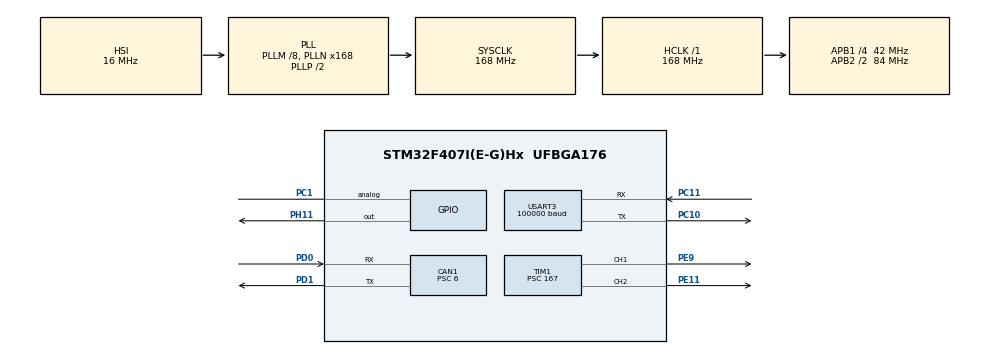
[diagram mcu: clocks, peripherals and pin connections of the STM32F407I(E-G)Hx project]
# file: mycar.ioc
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CAN1.BS1=CAN_BS1_3TQ
CAN1.BS2=CAN_BS2_3TQ
CAN1.CalculateBaudRate=1000000
CAN1.CalculateTimeBit=1000
CAN1.CalculateTimeQuantum=142.85714285714286
CAN1.Prescaler=6
Dma.Request0=USART3_RX
Dma.USART3_RX.0.Direction=DMA_PERIPH_TO_MEMORY
Dma.USART3_RX.0.FIFOMode=DMA_FIFOMODE_DISABLE
Dma.USART3_RX.0.Instance=DMA1_Stream1
Dma.USART3_RX.0.MemDataAlignment=DMA_MDATAALIGN_BYTE
Dma.USART3_RX.0.MemInc=DMA_MINC_ENABLE
Dma.USART3_RX.0.Mode=DMA_NORMAL
Dma.USART3_RX.0.PeriphDataAlignment=DMA_PDATAALIGN_BYTE
Dma.USART3_RX.0.PeriphInc=DMA_PINC_DISABLE
Dma.USART3_RX.0.Priority=DMA_PRIORITY_LOW
FREERTOS.INCLUDE_eTaskGetState=1
FREERTOS.INCLUDE_pcTaskGetTaskName=1
FREERTOS.INCLUDE_uxTaskGetStackHighWaterMark=1
FREERTOS.INCLUDE_vTaskCleanUpResources=1
FREERTOS.INCLUDE_vTaskDelayUntil=1
FREERTOS.INCLUDE_xEventGroupSetBitFromISR=1
FREERTOS.INCLUDE_xQueueGetMutexHolder=1
FREERTOS.INCLUDE_xSemaphoreGetMutexHolder=1
FREERTOS.INCLUDE_xTaskAbortDelay=1
FREERTOS.INCLUDE_xTaskGetCurrentTaskHandle=1
FREERTOS.INCLUDE_xTaskGetHandle=1
FREERTOS.INCLUDE_xTimerPendFunctionCall=1
FREERTOS.Tasks01=defaultTask,0,128,StartDefaultTask,Default,NULL,Dynamic,NULL,NULL;gimbaltask,2,256,Startgimbaltask,Default,NULL,Dynamic,NULL,NULL;chassistask,2,256,Startchassistask,Default,NULL,Dynamic,NULL,NULL;decodeTask,3,256,StartdecodeTask,Default,NULL,Dynamic,NULL,NULL;sendTask,0,128,StartsendTask,Default,NULL,Dynamic,NULL,NULL;modeTask,1,256,StartmodeTask,Default,NULL,Dynamic,NULL,NULL
FREERTOS.configUSE_TIMERS=1
Mcu.Family=STM32F4
Mcu.Name=STM32F407I(E-G)Hx
Mcu.Package=UFBGA176
NVIC.CAN1_RX0_IRQn=true\:5\:0\:false\:false\:true\:true\:true\:true\:true
NVIC.DMA1_Stream1_IRQn=true\:5\:0\:false\:false\:true\:true\:false\:true\:true
NVIC.PriorityGroup=NVIC_PRIORITYGROUP_4
NVIC.TIM2_IRQn=true\:15\:0\:false\:false\:true\:false\:false\:true\:true
NVIC.TimeBase=TIM2_IRQn
NVIC.TimeBaseIP=TIM2
NVIC.USART3_IRQn=true\:5\:0\:false\:false\:true\:true\:true\:true\:true
PA13.Mode=Serial_Wire
PA13.Signal=SYS_JTMS-SWDIO
PA14.Mode=Serial_Wire
PA14.Signal=SYS_JTCK-SWCLK
PC1.Signal=GPIO_Analog
PC10.Mode=Asynchronous
PC10.Signal=USART3_TX
PC11.Mode=Asynchronous
PC11.Signal=USART3_RX
PD0.Mode=CAN_Activate
PD0.Signal=CAN1_RX
PD1.Mode=CAN_Activate
PD1.Signal=CAN1_TX
PE11.Signal=S_TIM1_CH2
PE9.Signal=S_TIM1_CH1
PH0-OSC_IN.Mode=HSE-External-Oscillator
PH0-OSC_IN.Signal=RCC_OSC_IN
PH1-OSC_OUT.Mode=HSE-External-Oscillator
PH1-OSC_OUT.Signal=RCC_OSC_OUT
PH11.GPIO_PuPd=GPIO_PULLUP
PH11.PinState=GPIO_PIN_SET
PH11.Signal=GPIO_Output
ProjectManager.HeapSize=0x200
ProjectManager.StackSize=0x400
ProjectManager.TargetToolchain=CMake
RCC.48MHZClocksFreq_Value=84000000
RCC.AHBFreq_Value=168000000
RCC.APB1CLKDivider=RCC_HCLK_DIV4
RCC.APB1Freq_Value=42000000
RCC.APB1TimFreq_Value=84000000
RCC.APB2CLKDivider=RCC_HCLK_DIV2
RCC.APB2Freq_Value=84000000
RCC.APB2TimFreq_Value=168000000
RCC.CortexFreq_Value=168000000
RCC.HCLKFreq_Value=168000000
RCC.HSE_VALUE=12000000
RCC.HSI_VALUE=16000000
RCC.LSE_VALUE=32768
RCC.PLLM=8
RCC.PLLN=168
RCC.SYSCLKFreq_VALUE=168000000
RCC.SYSCLKSource=RCC_SYSCLKSOURCE_PLLCLK
RCC.VCOOutputFreq_Value=336000000
SH.S_TIM1_CH1.0=TIM1_CH1,PWM Generation1 CH1
SH.S_TIM1_CH2.0=TIM1_CH2,PWM Generation2 CH2
STMicroelectronics.X-CUBE-ALGOBUILD.1.5.0.LibraryCcDSPOoLibraryJjDSPOoLibrary=true
TIM1.AutoReloadPreload=TIM_AUTORELOAD_PRELOAD_ENABLE
TIM1.Channel-PWM\ Generation1\ CH1=TIM_CHANNEL_1
TIM1.Channel-PWM\ Generation2\ CH2=TIM_CHANNEL_2
TIM1.Period=19999
TIM1.Prescaler=167
TIM1.Pulse-PWM\ Generation1\ CH1=1500
TIM1.Pulse-PWM\ Generation2\ CH2=1500
USART3.BaudRate=100000
USART3.Parity=PARITY_EVEN
USART3.VirtualMode=VM_ASYNC
USART3.WordLength=WORDLENGTH_9B
VP_FREERTOS_VS_CMSIS_V1.Mode=CMSIS_V1
VP_STMicroelectronics.X-CUBE-ALGOBUILD_VS_DSPOoLibraryJjLibrary_1.5.0_1.5.0.Mode=DSPOoLibraryJjLibrary
VP_SYS_VS_tim2.Mode=TIM2
VP_TIM1_VS_ClockSourceINT.Mode=Internal
board=custom

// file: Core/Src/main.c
/* USER CODE BEGIN Header */
/**
  ******************************************************************************
  * @file           : main.c
  * @brief          : Main program body
  ******************************************************************************
  * @attention
  *
  * Copyright (c) 2026 STMicroelectronics.
  * All rights reserved.
  *
  * This software is licensed under terms that can be found in the LICENSE file
  * in the root directory of this software component.
  * If no LICENSE file comes with this software, it is provided AS-IS.
  *
  ******************************************************************************
  */
/* USER CODE END Header */
#include "main.h"
#include "cmsis_os.h"
#include "can.h"
#include "dma.h"
#include "tim.h"
#include "usart.h"
#include "gpio.h"

/* USER CODE BEGIN Includes */
#include "bsp_dwt.h"
#include "mycar.h"
/* USER CODE END Includes */

void SystemClock_Config(void);
void MX_FREERTOS_Init(void);

int main(void)
{

  /* MCU Configuration--------------------------------------------------------*/

  /* Reset of all peripherals, Initializes the Flash interface and the Systick. */
  HAL_Init();

  /* Configure the system clock */
  SystemClock_Config();

  /* Initialize all configured peripherals */
  MX_GPIO_Init();
  MX_DMA_Init();
  MX_CAN1_Init();
  MX_USART3_UART_Init();
  MX_TIM1_Init();
  /* USER CODE BEGIN 2 */

  DWT_Init(168);
  TotalCar_Init();
  /* USER CODE END 2 */

  /* Call init function for freertos objects (in cmsis_os2.c) */
  MX_FREERTOS_Init();

  /* Start scheduler */
  osKernelStart();

  /* We should never get here as control is now taken by the scheduler */

  /* Infinite loop */
  while (1)
  {

  }
}

void SystemClock_Config(void)
{
  RCC_OscInitTypeDef RCC_OscInitStruct = {0};
  RCC_ClkInitTypeDef RCC_ClkInitStruct = {0};

  /** Configure the main internal regulator output voltage
  */
  __HAL_RCC_PWR_CLK_ENABLE();
  __HAL_PWR_VOLTAGESCALING_CONFIG(PWR_REGULATOR_VOLTAGE_SCALE1);

  /** Initializes the RCC Oscillators according to the specified parameters
  * in the RCC_OscInitTypeDef structure.
  */
  RCC_OscInitStruct.OscillatorType = RCC_OSCILLATORTYPE_HSI;
  RCC_OscInitStruct.HSIState = RCC_HSI_ON;
  RCC_OscInitStruct.HSICalibrationValue = RCC_HSICALIBRATION_DEFAULT;
  RCC_OscInitStruct.PLL.PLLState = RCC_PLL_ON;
  RCC_OscInitStruct.PLL.PLLSource = RCC_PLLSOURCE_HSI;
  RCC_OscInitStruct.PLL.PLLM = 8;
  RCC_OscInitStruct.PLL.PLLN = 168;
  RCC_OscInitStruct.PLL.PLLP = RCC_PLLP_DIV2;
  RCC_OscInitStruct.PLL.PLLQ = 4;
  if (HAL_RCC_OscConfig(&RCC_OscInitStruct) != HAL_OK)
  {
    Error_Handler();
  }

  /** Initializes the CPU, AHB and APB buses clocks
  */
  RCC_ClkInitStruct.ClockType = RCC_CLOCKTYPE_HCLK|RCC_CLOCKTYPE_SYSCLK
                              |RCC_CLOCKTYPE_PCLK1|RCC_CLOCKTYPE_PCLK2;
  RCC_ClkInitStruct.SYSCLKSource = RCC_SYSCLKSOURCE_PLLCLK;
  RCC_ClkInitStruct.AHBCLKDivider = RCC_SYSCLK_DIV1;
  RCC_ClkInitStruct.APB1CLKDivider = RCC_HCLK_DIV4;
  RCC_ClkInitStruct.APB2CLKDivider = RCC_HCLK_DIV2;

  if (HAL_RCC_ClockConfig(&RCC_ClkInitStruct, FLASH_LATENCY_5) != HAL_OK)
  {
    Error_Handler();
  }
}

void HAL_TIM_PeriodElapsedCallback(TIM_HandleTypeDef *htim)
{
  if (htim->Instance == TIM2)
  {
    HAL_IncTick();
  }
}

void Error_Handler(void)
{
  __disable_irq();
  while (1)
  {
  }
}

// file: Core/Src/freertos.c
/* USER CODE BEGIN Header */
/**
  ******************************************************************************
  * File Name          : freertos.c
  * Description        : Code for freertos applications
  ******************************************************************************
  * @attention
  *
  * Copyright (c) 2026 STMicroelectronics.
  * All rights reserved.
  *
  * This software is licensed under terms that can be found in the LICENSE file
  * in the root directory of this software component.
  * If no LICENSE file comes with this software, it is provided AS-IS.
  *
  ******************************************************************************
  */
/* USER CODE END Header */

#include "FreeRTOS.h"
#include "task.h"
#include "main.h"
#include "cmsis_os.h"

/* USER CODE BEGIN Includes */
#include "mycar.h"
/* USER CODE END Includes */

osThreadId defaultTaskHandle;
osThreadId gimbaltaskHandle;
osThreadId chassistaskHandle;
osThreadId decodeTaskHandle;
osThreadId sendTaskHandle;
osThreadId modeTaskHandle;

void StartDefaultTask(void const * argument);
void Startgimbaltask(void const * argument);
void Startchassistask(void const * argument);
void StartdecodeTask(void const * argument);
void StartsendTask(void const * argument);
void StartmodeTask(void const * argument);

void MX_FREERTOS_Init(void); /* (MISRA C 2004 rule 8.1) */

/* GetIdleTaskMemory prototype (linked to static allocation support) */
void vApplicationGetIdleTaskMemory( StaticTask_t **ppxIdleTaskTCBBuffer, StackType_t **ppxIdleTaskStackBuffer, uint32_t *pulIdleTaskStackSize );

/* GetTimerTaskMemory prototype (linked to static allocation support) */
void vApplicationGetTimerTaskMemory( StaticTask_t **ppxTimerTaskTCBBuffer, StackType_t **ppxTimerTaskStackBuffer, uint32_t *pulTimerTaskStackSize );

/* USER CODE BEGIN GET_IDLE_TASK_MEMORY */
static StaticTask_t xIdleTaskTCBBuffer;
static StackType_t xIdleStack[configMINIMAL_STACK_SIZE];

void vApplicationGetIdleTaskMemory( StaticTask_t **ppxIdleTaskTCBBuffer, StackType_t **ppxIdleTaskStackBuffer, uint32_t *pulIdleTaskStackSize )
{
  *ppxIdleTaskTCBBuffer = &xIdleTaskTCBBuffer;
  *ppxIdleTaskStackBuffer = &xIdleStack[0];
  *pulIdleTaskStackSize = configMINIMAL_STACK_SIZE;
  /* place for user code */
}
/* USER CODE END GET_IDLE_TASK_MEMORY */

/* USER CODE BEGIN GET_TIMER_TASK_MEMORY */
static StaticTask_t xTimerTaskTCBBuffer;
static StackType_t xTimerStack[configTIMER_TASK_STACK_DEPTH];

void vApplicationGetTimerTaskMemory( StaticTask_t **ppxTimerTaskTCBBuffer, StackType_t **ppxTimerTaskStackBuffer, uint32_t *pulTimerTaskStackSize )
{
  *ppxTimerTaskTCBBuffer = &xTimerTaskTCBBuffer;
  *ppxTimerTaskStackBuffer = &xTimerStack[0];
  *pulTimerTaskStackSize = configTIMER_TASK_STACK_DEPTH;
  /* place for user code */
}
/* USER CODE END GET_TIMER_TASK_MEMORY */

void MX_FREERTOS_Init(void) {

  /* Create the thread(s) */
  /* definition and creation of defaultTask */
  osThreadDef(defaultTask, StartDefaultTask, osPriorityNormal, 0, 128);
  defaultTaskHandle = osThreadCreate(osThread(defaultTask), NULL);

  /* definition and creation of gimbaltask */
  osThreadDef(gimbaltask, Startgimbaltask, osPriorityHigh, 0, 256);
  gimbaltaskHandle = osThreadCreate(osThread(gimbaltask), NULL);

  /* definition and creation of chassistask */
  osThreadDef(chassistask, Startchassistask, osPriorityHigh, 0, 256);
  chassistaskHandle = osThreadCreate(osThread(chassistask), NULL);

  /* definition and creation of decodeTask */
  osThreadDef(decodeTask, StartdecodeTask, osPriorityRealtime, 0, 256);
  decodeTaskHandle = osThreadCreate(osThread(decodeTask), NULL);

  /* definition and creation of sendTask */
  osThreadDef(sendTask, StartsendTask, osPriorityNormal, 0, 128);
  sendTaskHandle = osThreadCreate(osThread(sendTask), NULL);

  /* definition and creation of modeTask */
  osThreadDef(modeTask, StartmodeTask, osPriorityAboveNormal, 0, 256);
  modeTaskHandle = osThreadCreate(osThread(modeTask), NULL);

}

void StartDefaultTask(void const * argument)
{
  /* USER CODE BEGIN StartDefaultTask */
  /* Infinite loop */
  for(;;)
  {
    HAL_GPIO_TogglePin(GPIOH,GPIO_PIN_11);
    osDelay(100);

  }
  /* USER CODE END StartDefaultTask */
}

void Startgimbaltask(void const * argument)
{
  /* USER CODE BEGIN Startgimbaltask */
  Gimbal_Init();
  /* Infinite loop */
  for(;;)
  {
    Gimbal_Task();
    osDelay(1);
  }
  /* USER CODE END Startgimbaltask */
}

void Startchassistask(void const * argument)
{
  /* USER CODE BEGIN Startchassistask */
  Chassis_Init();
  /* Infinite loop */
  for(;;)
  {
    Chassis_Task();
    osDelay(1);
  }
  /* USER CODE END Startchassistask */
}

void StartdecodeTask(void const * argument)
{
  /* USER CODE BEGIN StartdecodeTask */
  /* Infinite loop */
  for(;;)
  {
    Decode_Task();
    osDelay(1);
  }
  /* USER CODE END StartdecodeTask */
}

void StartsendTask(void const * argument)
{
  /* USER CODE BEGIN StartsendTask */
  /* Infinite loop */
  for(;;)
  {
    Send_Task();
    osDelay(1);
  }
  /* USER CODE END StartsendTask */
}

void StartmodeTask(void const * argument)
{
  /* USER CODE BEGIN StartmodeTask */
  /* Infinite loop */
  for(;;)
  {
    Mode_Task();
    osDelay(1);
  }
  /* USER CODE END StartmodeTask */
}
